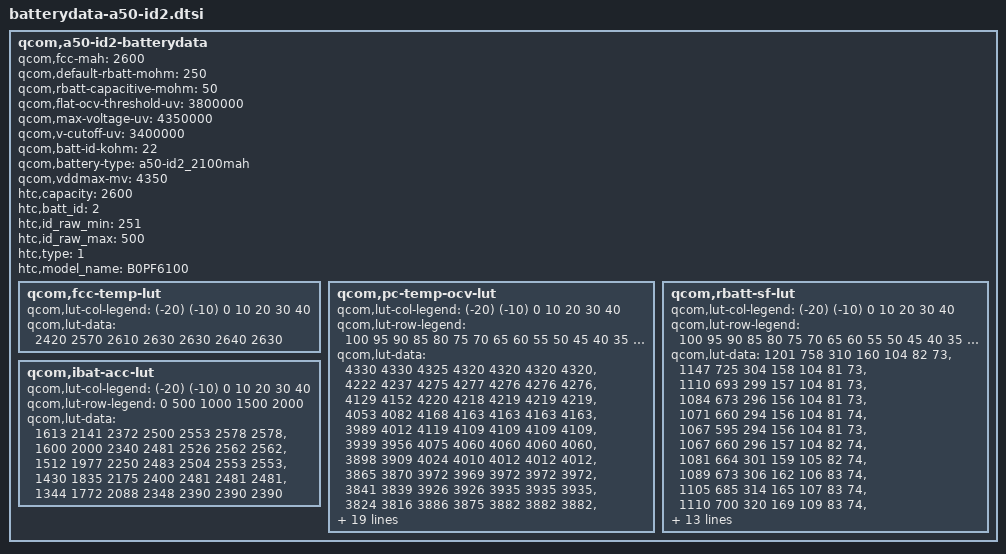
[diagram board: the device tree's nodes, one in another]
/* Copyright (c) 2013, The Linux Foundation. All rights reserved.
 *
 * This program is free software; you can redistribute it and/or modify
 * it under the terms of the GNU General Public License version 2 and
 * only version 2 as published by the Free Software Foundation.
 *
 * This program is distributed in the hope that it will be useful,
 * but WITHOUT ANY WARRANTY; without even the implied warranty of
 * MERCHANTABILITY or FITNESS FOR A PARTICULAR PURPOSE.  See the
 * GNU General Public License for more details.
 */

qcom,a50-id2-batterydata {
	qcom,fcc-mah = <2600>;
	qcom,default-rbatt-mohm = <250>;
	qcom,rbatt-capacitive-mohm = <50>;
	qcom,flat-ocv-threshold-uv = <3800000>;
	qcom,max-voltage-uv = <4350000>;
	qcom,v-cutoff-uv = <3400000>;
	qcom,batt-id-kohm = <22>;
	qcom,battery-type = "a50-id2_2100mah";
	qcom,vddmax-mv = <4350>;
	htc,capacity = <2600>;
	htc,batt_id = <2>;
	htc,id_raw_min = <251>;
	htc,id_raw_max = <500>;
	htc,type = <1>;
	htc,model_name = "B0PF6100";

	qcom,fcc-temp-lut {
		qcom,lut-col-legend = <(-20) (-10) 0 10 20 30 40>;
		qcom,lut-data = <2420 2570 2610 2630 2630 2640 2630>;
	};

	qcom,pc-temp-ocv-lut {
		qcom,lut-col-legend = <(-20) (-10) 0 10 20 30 40>;
		qcom,lut-row-legend = <100 95 90 85 80 75 70 65 60 55 50 45 40 35 30 25 20 15 10 9 8 7 6 5 4 3 2 1 0>;
		qcom,lut-data = <4330 4330 4325 4320 4320 4320 4320>,
						<4222 4237 4275 4277 4276 4276 4276>,
						<4129 4152 4220 4218 4219 4219 4219>,
						<4053 4082 4168 4163 4163 4163 4163>,
						<3989 4012 4119 4109 4109 4109 4109>,
						<3939 3956 4075 4060 4060 4060 4060>,
						<3898 3909 4024 4010 4012 4012 4012>,
						<3865 3870 3972 3969 3972 3972 3972>,
						<3841 3839 3926 3926 3935 3935 3935>,
						<3824 3816 3886 3875 3882 3882 3882>,
						<3810 3804 3855 3840 3842 3842 3842>,
						<3796 3793 3831 3816 3819 3819 3819>,
						<3781 3783 3811 3798 3801 3801 3801>,
						<3766 3771 3795 3785 3785 3785 3785>,
						<3750 3757 3783 3777 3772 3772 3772>,
						<3735 3737 3767 3768 3758 3758 3758>,
						<3720 3716 3733 3745 3733 3733 3733>,
						<3700 3676 3701 3700 3689 3689 3689>,
						<3674 3625 3686 3680 3675 3675 3675>,
						<3670 3617 3673 3677 3671 3671 3671>,
						<3667 3608 3661 3675 3668 3668 3668>,
						<3659 3597 3631 3665 3657 3657 3657>,
						<3652 3585 3602 3656 3646 3646 3646>,
						<3643 3572 3560 3618 3601 3601 3601>,
						<3634 3558 3517 3579 3555 3555 3555>,
						<3622 3542 3462 3501 3473 3473 3473>,
						<3611 3525 3406 3424 3391 3391 3391>,
						<3598 3499 3309 3222 3195 3195 3195>,
						<3585 3472 3213 3020 3000 3000 3000>;
	};

	qcom,rbatt-sf-lut {
		qcom,lut-col-legend = <(-20) (-10) 0 10 20 30 40>;
		qcom,lut-row-legend = <100 95 90 85 80 75 70 65 60 55 50 45 40 35 30 25 20 15 10 8 6 4 2 0>;
		qcom,lut-data = <1201 758 310 160 104 82 73>,
						<1147 725 304 158 104 81 73>,
						<1110 693 299 157 104 81 73>,
						<1084 673 296 156 104 81 73>,
						<1071 660 294 156 104 81 74>,
						<1067 595 294 156 104 81 73>,
						<1067 660 296 157 104 82 74>,
						<1081 664 301 159 105 82 74>,
						<1089 673 306 162 106 83 74>,
						<1105 685 314 165 107 83 74>,
						<1110 700 320 169 109 83 74>,
						<1118 717 331 168 110 84 74>,
						<1129 728 343 180 113 85 75>,
						<1139 744 357 189 116 85 76>,
						<1145 755 368 201 120 87 76>,
						<1190 770 381 211 126 90 78>,
						<1222 805 401 222 131 92 79>,
						<1234 826 414 237 138 94 80>,
						<1245 831 421 250 149 98 82>,
						<1268 838 430 257 213 99 87>,
						<1270 852 436 266 223 102 88>,
						<1274 866 454 280 232 109 96>,
						<1293 871 470 299 238 115 119>,
						<1315 881 495 351 242 149 126>;
	};

	qcom,ibat-acc-lut {
		qcom,lut-col-legend = <(-20) (-10) 0 10 20 30 40>;
		qcom,lut-row-legend = <0 500 1000 1500 2000>;
		qcom,lut-data = <1613 2141 2372 2500 2553 2578 2578>,
						<1600 2000 2340 2481 2526 2562 2562>,
						<1512 1977 2250 2483 2504 2553 2553>,
						<1430 1835 2175 2400 2481 2481 2481>,
						<1344 1772 2088 2348 2390 2390 2390>;
	};
};
